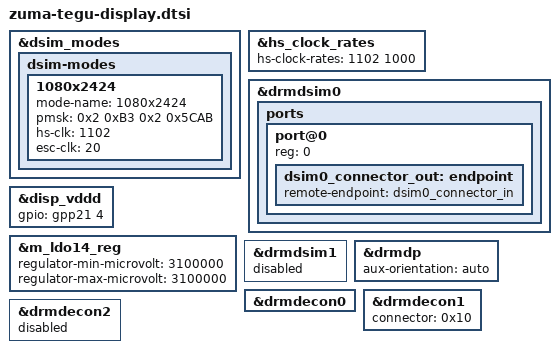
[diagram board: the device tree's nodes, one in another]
// SPDX-License-Identifier: GPL-2.0-only
/*
 * Display nodes for tegu-related boards.
 *
 * Copyright 2023 Google LLC
 *
 */

#include <dt-bindings/gpio/gpio.h>
#include "zuma-tegu-connector.dtsi"

&dsim_modes {
	dsim-modes {
		1080x2424 {
			mode-name = "1080x2424";
			pmsk = <
				0x2 0xB3 0x2 0x5CAB /* p m s k */
				>;
			hs-clk = <1102>;
			esc-clk = <20>;
		};
	};
};

&hs_clock_rates {
	hs-clock-rates = <1102 1000>;
};

&drmdsim0 {
	#address-cells = <1>;
	#size-cells = <0>;

	ports {
		#address-cells = <1>;
		#size-cells = <0>;
		port@0 {
			reg = <0>;
			/* output */
			dsim0_connector_out: endpoint {
				remote-endpoint = <&dsim0_connector_in>;
			};
		};
	};
};

&disp_vddd {
	status = "okay";
	gpio = <&gpp21 4 GPIO_ACTIVE_HIGH>;
};

&m_ldo14_reg {
	regulator-min-microvolt = <3100000>;
	regulator-max-microvolt = <3100000>;
};

&drmdsim1 {
	status = "disabled";
};

&drmdp {
	status = "okay";
	aux-orientation = "auto";
};

&drmdecon0 {
	status = "okay";
};

&drmdecon1 {
	status = "okay";
	connector = <0x10>;
};

&drmdecon2 {
	status = "disabled";
};
